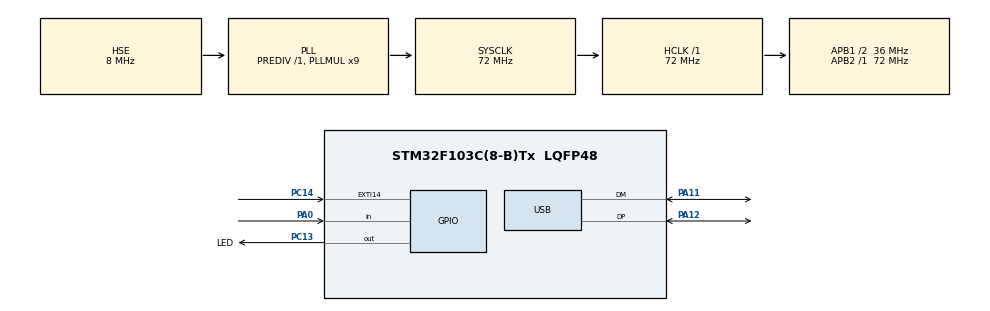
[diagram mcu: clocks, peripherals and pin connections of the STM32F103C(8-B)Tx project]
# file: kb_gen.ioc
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Mcu.Family=STM32F1
Mcu.Name=STM32F103C(8-B)Tx
Mcu.Package=LQFP48
NVIC.EXTI15_10_IRQn=true\:0\:0\:false\:false\:true\:true\:true\:true
NVIC.PriorityGroup=NVIC_PRIORITYGROUP_4
NVIC.USB_LP_CAN1_RX0_IRQn=true\:0\:0\:false\:false\:true\:false\:true\:true
PA0-WKUP.GPIO_PuPd=GPIO_PULLUP
PA0-WKUP.Signal=GPIO_Input
PA11.Mode=Device
PA11.Signal=USB_DM
PA12.Mode=Device
PA12.Signal=USB_DP
PA13.Mode=Trace_Asynchronous_SW
PA13.Signal=SYS_JTMS-SWDIO
PA14.Mode=Trace_Asynchronous_SW
PA14.Signal=SYS_JTCK-SWCLK
PB3.Mode=Trace_Asynchronous_SW
PB3.Signal=SYS_JTDO-TRACESWO
PC13-TAMPER-RTC.GPIO_Label=LED
PC13-TAMPER-RTC.GPIO_PuPd=GPIO_PULLDOWN
PC13-TAMPER-RTC.Signal=GPIO_Output
PC14-OSC32_IN.GPIO_ModeDefaultEXTI=GPIO_MODE_IT_FALLING
PC14-OSC32_IN.GPIO_PuPd=GPIO_PULLUP
PC14-OSC32_IN.Signal=GPXTI14
PD0-OSC_IN.Mode=HSE-External-Oscillator
PD0-OSC_IN.Signal=RCC_OSC_IN
PD1-OSC_OUT.Mode=HSE-External-Oscillator
PD1-OSC_OUT.Signal=RCC_OSC_OUT
ProjectManager.HeapSize=0x400
ProjectManager.StackSize=0x2000
ProjectManager.TargetToolchain=Makefile
RCC.AHBFreq_Value=72000000
RCC.APB1CLKDivider=RCC_HCLK_DIV2
RCC.APB1Freq_Value=36000000
RCC.APB1TimFreq_Value=72000000
RCC.APB2Freq_Value=72000000
RCC.APB2TimFreq_Value=72000000
RCC.HCLKFreq_Value=72000000
RCC.PLLMUL=RCC_PLL_MUL9
RCC.SYSCLKFreq_VALUE=72000000
RCC.SYSCLKSource=RCC_SYSCLKSOURCE_PLLCLK
RCC.USBFreq_Value=48000000
RCC.USBPrescaler=RCC_USBCLKSOURCE_PLL_DIV1_5
USB_DEVICE.CLASS_NAME_FS=HID
USB_DEVICE.HID_FS_BINTERVAL=0x5
USB_DEVICE.VirtualMode=Hid
USB_DEVICE.VirtualModeFS=Hid_FS
VP_USB_DEVICE_VS_USB_DEVICE_HID_FS.Mode=HID_FS
board=custom

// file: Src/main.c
/* USER CODE BEGIN Header */
/**
 ******************************************************************************
 * @file           : main.c
 * @brief          : Main program body
 ******************************************************************************
 * @attention
 *
 * Copyright (c) 2023 STMicroelectronics.
 * All rights reserved.
 *
 * This software is licensed under terms that can be found in the LICENSE file
 * in the root directory of this software component.
 * If no LICENSE file comes with this software, it is provided AS-IS.
 *
 ******************************************************************************
 */
/* USER CODE END Header */
#include "main.h"
#include "usb_device.h"
#include "gpio.h"

/* USER CODE BEGIN Includes */
#include "kb_hid.h"
#include "keyboard.h"

/* USER CODE END Includes */

/* USER CODE BEGIN PD */
extern USBD_HandleTypeDef hUsbDeviceFS;

/* USER CODE END PD */

void SystemClock_Config(void);

int main(void) {
  /* USER CODE BEGIN 1 */
  Reset_USB();
  /* USER CODE END 1 */

  /* MCU Configuration--------------------------------------------------------*/

  /* Reset of all peripherals, Initializes the Flash interface and the Systick.
   */
  HAL_Init();

  /* Configure the system clock */
  SystemClock_Config();

  /* Initialize all configured peripherals */
  MX_GPIO_Init();
  MX_USB_DEVICE_Init();

  /* Infinite loop */
  /* USER CODE BEGIN WHILE */
  HAL_Delay(500);
  HAL_GPIO_WritePin(GPIOC, GPIO_PIN_13, GPIO_PIN_SET);
  while (1) {
    // swvPrint(0, "hello test\n");
    /* USER CODE END WHILE */

  }
}

void SystemClock_Config(void) {
  RCC_OscInitTypeDef RCC_OscInitStruct = {0};
  RCC_ClkInitTypeDef RCC_ClkInitStruct = {0};
  RCC_PeriphCLKInitTypeDef PeriphClkInit = {0};

  /** Initializes the RCC Oscillators according to the specified parameters
   * in the RCC_OscInitTypeDef structure.
   */
  RCC_OscInitStruct.OscillatorType = RCC_OSCILLATORTYPE_HSE;
  RCC_OscInitStruct.HSEState = RCC_HSE_ON;
  RCC_OscInitStruct.HSEPredivValue = RCC_HSE_PREDIV_DIV1;
  RCC_OscInitStruct.HSIState = RCC_HSI_ON;
  RCC_OscInitStruct.PLL.PLLState = RCC_PLL_ON;
  RCC_OscInitStruct.PLL.PLLSource = RCC_PLLSOURCE_HSE;
  RCC_OscInitStruct.PLL.PLLMUL = RCC_PLL_MUL9;
  if (HAL_RCC_OscConfig(&RCC_OscInitStruct) != HAL_OK) {
    Error_Handler();
  }

  /** Initializes the CPU, AHB and APB buses clocks
   */
  RCC_ClkInitStruct.ClockType = RCC_CLOCKTYPE_HCLK | RCC_CLOCKTYPE_SYSCLK |
                                RCC_CLOCKTYPE_PCLK1 | RCC_CLOCKTYPE_PCLK2;
  RCC_ClkInitStruct.SYSCLKSource = RCC_SYSCLKSOURCE_PLLCLK;
  RCC_ClkInitStruct.AHBCLKDivider = RCC_SYSCLK_DIV1;
  RCC_ClkInitStruct.APB1CLKDivider = RCC_HCLK_DIV2;
  RCC_ClkInitStruct.APB2CLKDivider = RCC_HCLK_DIV1;

  if (HAL_RCC_ClockConfig(&RCC_ClkInitStruct, FLASH_LATENCY_2) != HAL_OK) {
    Error_Handler();
  }
  PeriphClkInit.PeriphClockSelection = RCC_PERIPHCLK_USB;
  PeriphClkInit.UsbClockSelection = RCC_USBCLKSOURCE_PLL_DIV1_5;
  if (HAL_RCCEx_PeriphCLKConfig(&PeriphClkInit) != HAL_OK) {
    Error_Handler();
  }
}

/* USER CODE BEGIN 4 */
/**
 * Moved from stm32f1xx_it.c to here. 1ms
 * @brief This function handles System tick timer.
 */
uint8_t nextOp = 0;
uint8_t tick_count = 0;
void SysTick_Handler(void) {
  /* USER CODE BEGIN SysTick_IRQn 0 */

  /* USER CODE END SysTick_IRQn 0 */
  HAL_IncTick();
  /* USER CODE BEGIN SysTick_IRQn 1 */
  kb_scan_tick();
  /* USER CODE END SysTick_IRQn 1 */
}

/* USER CODE END 4 */

void Error_Handler(void) {
  __disable_irq();
  while (1) {
  }
}

#ifdef USE_FULL_ASSERT
/**
 * @brief  Reports the name of the source file and the source line number
 *         where the assert_param error has occurred.
 * @param  file: pointer to the source file name
 * @param  line: assert_param error line source number
 * @retval None
 */
void assert_failed(uint8_t *file, uint32_t line) {
  /* USER CODE BEGIN 6 */
  /* User can add his own implementation to report the file name and line
     number, ex: printf("Wrong parameters value: file %s on line %d\r\n", file,
     line) */
  /* USER CODE END 6 */
}
#endif /* USE_FULL_ASSERT */
